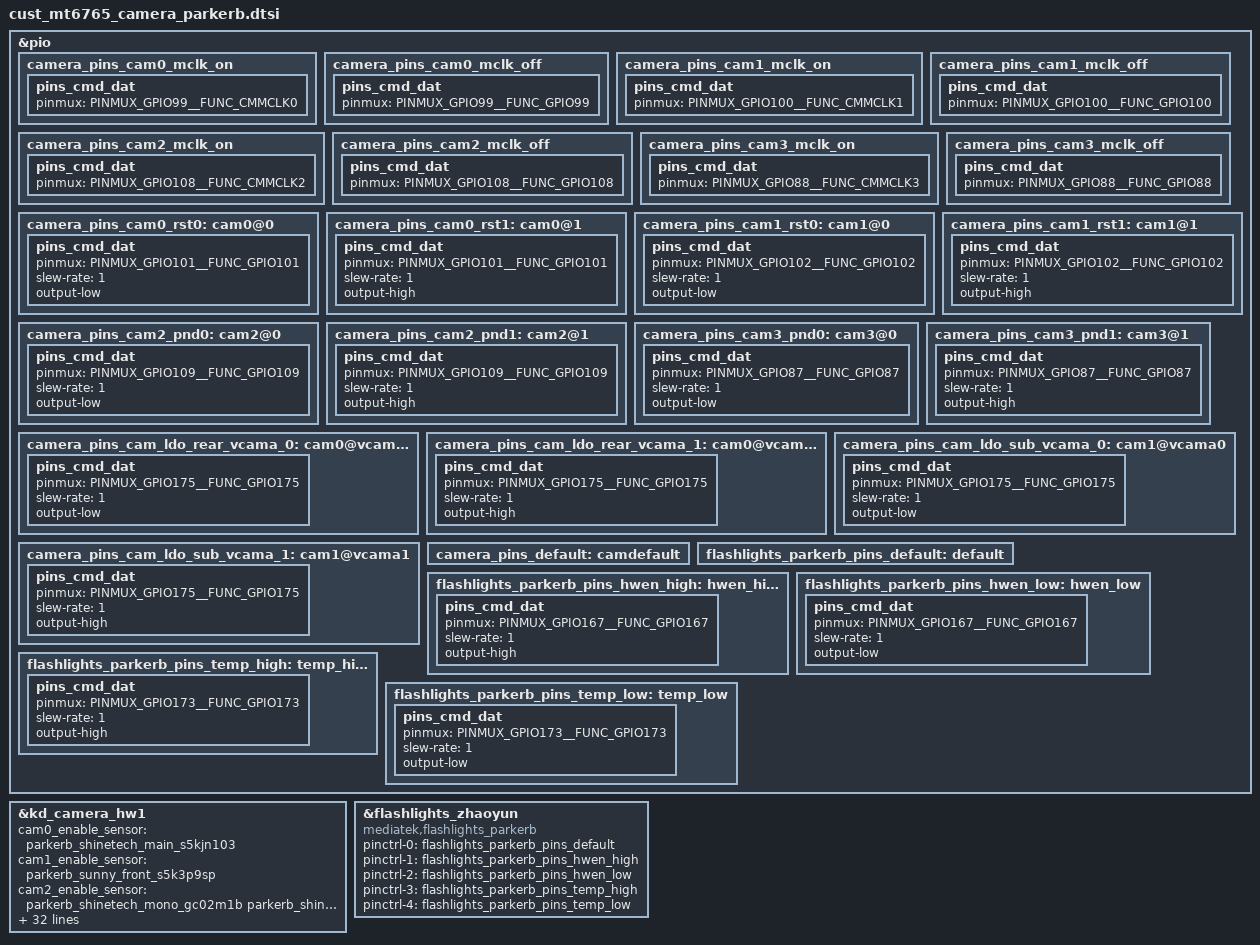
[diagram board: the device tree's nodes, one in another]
// SPDX-License-Identifier: GPL-2.0+
/*
 * Copyright (c) 2019 MediaTek Inc.
 *
 */

/* CAMERA GPIO standardization */
&pio {
	camera_pins_cam0_mclk_on: camera_pins_cam0_mclk_on {
		pins_cmd_dat {
			pinmux = <PINMUX_GPIO99__FUNC_CMMCLK0>;
		};
	};
	camera_pins_cam0_mclk_off: camera_pins_cam0_mclk_off {
		pins_cmd_dat {
			pinmux = <PINMUX_GPIO99__FUNC_GPIO99>;
		};
	};
	camera_pins_cam1_mclk_on: camera_pins_cam1_mclk_on {
		pins_cmd_dat {
			pinmux = <PINMUX_GPIO100__FUNC_CMMCLK1>;
		};
	};
	camera_pins_cam1_mclk_off: camera_pins_cam1_mclk_off {
		pins_cmd_dat {
			pinmux = <PINMUX_GPIO100__FUNC_GPIO100>;
		};
	};
	camera_pins_cam2_mclk_on: camera_pins_cam2_mclk_on {
		pins_cmd_dat {
			pinmux = <PINMUX_GPIO108__FUNC_CMMCLK2>;
		};
	};
	camera_pins_cam2_mclk_off: camera_pins_cam2_mclk_off {
		pins_cmd_dat {
			pinmux = <PINMUX_GPIO108__FUNC_GPIO108>;
		};
	};
	camera_pins_cam3_mclk_on: camera_pins_cam3_mclk_on {
		pins_cmd_dat {
			pinmux = <PINMUX_GPIO88__FUNC_CMMCLK3>;
		};
	};
	camera_pins_cam3_mclk_off: camera_pins_cam3_mclk_off {
		pins_cmd_dat {
			pinmux = <PINMUX_GPIO88__FUNC_GPIO88>;
		};
	};
	camera_pins_cam0_rst0: cam0@0 {
		pins_cmd_dat {
			pinmux = <PINMUX_GPIO101__FUNC_GPIO101>;
			slew-rate = <1>;
			output-low;
		};
	};
	camera_pins_cam0_rst1: cam0@1 {
		pins_cmd_dat {
			pinmux = <PINMUX_GPIO101__FUNC_GPIO101>;
			slew-rate = <1>;
			output-high;
		};
	};
	camera_pins_cam1_rst0: cam1@0 {
		pins_cmd_dat {
			pinmux = <PINMUX_GPIO102__FUNC_GPIO102>;
			slew-rate = <1>;
			output-low;
		};
	};
	camera_pins_cam1_rst1: cam1@1 {
		pins_cmd_dat {
			pinmux = <PINMUX_GPIO102__FUNC_GPIO102>;
			slew-rate = <1>;
			output-high;
		};
	};
	camera_pins_cam2_pnd0: cam2@0 {
		pins_cmd_dat {
			pinmux = <PINMUX_GPIO109__FUNC_GPIO109>;
			slew-rate = <1>;
			output-low;
		};
	};
	camera_pins_cam2_pnd1: cam2@1 {
		pins_cmd_dat {
			pinmux = <PINMUX_GPIO109__FUNC_GPIO109>;
			slew-rate = <1>;
			output-high;
		};
	};
	camera_pins_cam3_pnd0: cam3@0 {
		pins_cmd_dat {
			pinmux = <PINMUX_GPIO87__FUNC_GPIO87>;
			slew-rate = <1>;
			output-low;
		};
	};
	camera_pins_cam3_pnd1: cam3@1 {
		pins_cmd_dat {
			pinmux = <PINMUX_GPIO87__FUNC_GPIO87>;
			slew-rate = <1>;
			output-high;
		};
	};
	camera_pins_cam_ldo_rear_vcama_0: cam0@vcama0 {
		pins_cmd_dat {
			pinmux = <PINMUX_GPIO175__FUNC_GPIO175>;
			slew-rate = <1>;
			output-low;
		};
	};
	camera_pins_cam_ldo_rear_vcama_1: cam0@vcama1 {
		pins_cmd_dat {
			pinmux = <PINMUX_GPIO175__FUNC_GPIO175>;
			slew-rate = <1>;
			output-high;
		};
	};
	camera_pins_cam_ldo_sub_vcama_0: cam1@vcama0 {
		pins_cmd_dat {
			pinmux = <PINMUX_GPIO175__FUNC_GPIO175>;
			slew-rate = <1>;
			output-low;
		};
	};
	camera_pins_cam_ldo_sub_vcama_1: cam1@vcama1 {
		pins_cmd_dat {
			pinmux = <PINMUX_GPIO175__FUNC_GPIO175>;
			slew-rate = <1>;
			output-high;
		};
	};
	camera_pins_default: camdefault {
	};

};

&kd_camera_hw1 {
	cam0_enable_sensor = "parkerb_shinetech_main_s5kjn103";
	cam1_enable_sensor = "parkerb_sunny_front_s5k3p9sp";
	cam2_enable_sensor = "parkerb_shinetech_mono_gc02m1b parkerb_shinetech_mono_ov02b1b";
	cam3_enable_sensor = "parkerb_hlt_micro_gc02m1 parkerb_shinetech_macro_ov02b10";
	pinctrl-names = "default",
			"cam0_rst0",
			"cam0_rst1",
			"cam1_rst0",
			"cam1_rst1",
			"cam2_pnd0",
			"cam2_pnd1",
			"cam3_pnd0",
			"cam3_pnd1",
			"cam0_vcama_on",
			"cam0_vcama_off",
			"cam1_vcama_on",
			"cam1_vcama_off",
			"cam0_mclk_on",
			"cam0_mclk_off",
			"cam1_mclk_on",
			"cam1_mclk_off",
			"cam2_mclk_on",
			"cam2_mclk_off",
			"cam3_mclk_on",
			"cam3_mclk_off";

	pinctrl-0 = <&camera_pins_default>;
	pinctrl-1 = <&camera_pins_cam0_rst0>;
	pinctrl-2 = <&camera_pins_cam0_rst1>;
	pinctrl-3 = <&camera_pins_cam1_rst0>;
	pinctrl-4 = <&camera_pins_cam1_rst1>;
	pinctrl-5 = <&camera_pins_cam2_pnd0>;
	pinctrl-6 = <&camera_pins_cam2_pnd1>;
	pinctrl-7 = <&camera_pins_cam3_pnd0>;
	pinctrl-8 = <&camera_pins_cam3_pnd1>;
	pinctrl-9 = <&camera_pins_cam_ldo_rear_vcama_1>;
	pinctrl-10 = <&camera_pins_cam_ldo_rear_vcama_0>;
	pinctrl-11 = <&camera_pins_cam_ldo_sub_vcama_1>;
	pinctrl-12 = <&camera_pins_cam_ldo_sub_vcama_0>;
	pinctrl-13 = <&camera_pins_cam0_mclk_on>;
	pinctrl-14 = <&camera_pins_cam0_mclk_off>;
	pinctrl-15 = <&camera_pins_cam1_mclk_on>;
	pinctrl-16 = <&camera_pins_cam1_mclk_off>;
	pinctrl-17 = <&camera_pins_cam2_mclk_on>;
	pinctrl-18 = <&camera_pins_cam2_mclk_off>;
	pinctrl-19 = <&camera_pins_cam3_mclk_on>;
	pinctrl-20 = <&camera_pins_cam3_mclk_off>;

	cam0_vcamd-supply = <&mt_pmic_vcamd_ldo_reg>;//main DVDD
	cam0_vcamio-supply = <&mt_pmic_vcamio_ldo_reg>;//main IO
	cam0_vcamaf-supply = <&mt_pmic_vldo28_ldo_reg>;//main af
	cam1_vcamd-supply = <&mt_pmic_vcamd_ldo_reg>;//sub DVDD
	cam1_vcamio-supply = <&mt_pmic_vcamio_ldo_reg>;//sub IO
	cam2_vcama-supply = <&mt_pmic_vcama_ldo_reg>;//depth DVDD
	cam2_vcamio-supply = <&mt_pmic_vcamio_ldo_reg>;//depth IO
	cam3_vcama-supply = <&mt_pmic_vcama_ldo_reg>;//macro AVDD
	cam3_vcamio-supply = <&mt_pmic_vcamio_ldo_reg>;//macro IO
	status = "okay";

};

&flashlights_zhaoyun {
	compatible = "mediatek,flashlights_parkerb";
	pinctrl-names = "parkerb_default",
			"parkerb_hwen_high",
			"parkerb_hwen_low",
			"parkerb_temp_high",
			"parkerb_temp_low";
	pinctrl-0 = <&flashlights_parkerb_pins_default>;
	pinctrl-1 = <&flashlights_parkerb_pins_hwen_high>;
	pinctrl-2 = <&flashlights_parkerb_pins_hwen_low>;
	pinctrl-3 = <&flashlights_parkerb_pins_temp_high>;
	pinctrl-4 = <&flashlights_parkerb_pins_temp_low>;
	status = "okay";
};

&pio {
	flashlights_parkerb_pins_default:default {
		};
	flashlights_parkerb_pins_hwen_high: hwen_high {
		pins_cmd_dat {
			pinmux = <PINMUX_GPIO167__FUNC_GPIO167>;
			slew-rate = <1>;
			output-high;
		};
	};
	flashlights_parkerb_pins_hwen_low: hwen_low {
		pins_cmd_dat {
			pinmux = <PINMUX_GPIO167__FUNC_GPIO167>;
			slew-rate = <1>;
			output-low;
		};
	};
	flashlights_parkerb_pins_temp_high: temp_high {
		pins_cmd_dat {
			pinmux = <PINMUX_GPIO173__FUNC_GPIO173>;
			slew-rate = <1>;
			output-high;
		};
	};
	flashlights_parkerb_pins_temp_low: temp_low {
		pins_cmd_dat {
			pinmux = <PINMUX_GPIO173__FUNC_GPIO173>;
			slew-rate = <1>;
			output-low;
		};
	};
};
/* CAMERA GPIO end */
